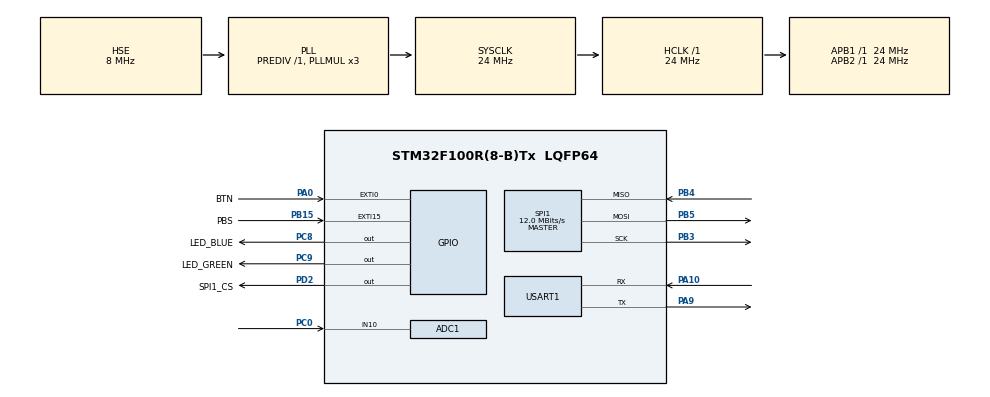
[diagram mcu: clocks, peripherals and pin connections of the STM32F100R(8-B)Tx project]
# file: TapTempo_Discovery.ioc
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Mcu.Family=STM32F1
TIM17.Prescaler=23999
VP_TIM17_VS_ClockSourceINT.Mode=Enable_Timer
ADC1.Rank-0\#ChannelRegularConversion=1
PD1-OSC_OUT.Mode=HSE-External-Oscillator
PA10.Mode=Asynchronous
SPI1.VirtualType=VM_MASTER
PC9.GPIO_Label=LED_GREEN
ADC1.ContinuousConvMode=ENABLE
TIM3.AutoReloadPreload=TIM_AUTORELOAD_PRELOAD_DISABLE
PC8.Signal=GPIO_Output
PD0-OSC_IN.Signal=RCC_OSC_IN
PC0.Signal=ADCx_IN10
PB15.Signal=GPXTI15
RCC.SYSCLKSource=RCC_SYSCLKSOURCE_PLLCLK
ProjectManager.StackSize=0x400
PA0-WKUP.GPIO_Label=BTN
PA0-WKUP.Signal=GPXTI0
RCC.PLLSource=RCC_PLLSOURCE_HSE
PD1-OSC_OUT.Signal=RCC_OSC_OUT
PC8.GPIO_Label=LED_BLUE
PA13.Signal=SYS_JTMS-SWDIO
PA9.Mode=Asynchronous
ProjectManager.TargetToolchain=STM32CubeIDE
SPI1.Direction=SPI_DIRECTION_2LINES
RCC.HCLKFreq_Value=24000000
RCC.APB2TimFreq_Value=24000000
TIM3.Period=25
PA9.Signal=USART1_TX
SPI1.CalculateBaudRate=12.0 MBits/s
RCC.AHBFreq_Value=24000000
PD0-OSC_IN.Mode=HSE-External-Oscillator
NVIC.EXTI15_10_IRQn=true\:1\:0\:true\:false\:true\:true\:true
ADC1.Channel-0\#ChannelRegularConversion=ADC_CHANNEL_10
PB15.GPIO_ModeDefaultEXTI=GPIO_MODE_IT_FALLING
PB3.Mode=Full_Duplex_Master
board=custom
RCC.PLLMUL=RCC_PLL_MUL3
NVIC.TIM3_IRQn=true\:0\:0\:false\:false\:true\:true\:true
TIM17.Period=1000
NVIC.TIM1_TRG_COM_TIM17_IRQn=true\:0\:0\:false\:false\:true\:true\:true
RCC.APB2Freq_Value=24000000
PB4.Mode=Full_Duplex_Master
PB15.GPIO_Label=PBS
VP_TIM2_VS_ClockSourceINT.Mode=Internal
SPI1.Mode=SPI_MODE_MASTER
PA14.Mode=Serial_Wire
TIM3.Prescaler=23999
PB5.Mode=Full_Duplex_Master
NVIC.TIM2_IRQn=true\:1\:0\:true\:false\:true\:true\:true
TIM2.Period=1000
PA13.Mode=Serial_Wire
Mcu.Name=STM32F100R(8-B)Tx
ADC1.SamplingTime-0\#ChannelRegularConversion=ADC_SAMPLETIME_1CYCLE_5
PB3.Signal=SPI1_SCK
NVIC.EXTI0_IRQn=true\:1\:0\:true\:false\:true\:true\:true
RCC.SYSCLKFreq_VALUE=24000000
Mcu.Package=LQFP64
PB5.Signal=SPI1_MOSI
TIM2.Prescaler=23999
ADC1.master=1
PB15.GPIO_PuPd=GPIO_PULLUP
USART1.VirtualMode=VM_ASYNC
PA10.Signal=USART1_RX
PA14.Signal=SYS_JTCK-SWCLK
SH.ADCx_IN10.0=ADC1_IN10,IN10
ProjectManager.HeapSize=0x200
NVIC.PriorityGroup=NVIC_PRIORITYGROUP_4
ADC1.NbrOfConversionFlag=1
RCC.APB1TimFreq_Value=24000000
TIM2.AutoReloadPreload=TIM_AUTORELOAD_PRELOAD_DISABLE
PC9.Signal=GPIO_Output
PD2.Signal=GPIO_Output
NVIC.USART1_IRQn=true\:0\:0\:false\:false\:true\:true\:true
RCC.APB1Freq_Value=24000000
SPI1.BaudRatePrescaler=SPI_BAUDRATEPRESCALER_2
VP_TIM3_VS_ClockSourceINT.Mode=Internal
PD2.GPIO_Label=SPI1_CS
PB4.Signal=SPI1_MISO

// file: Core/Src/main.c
/* USER CODE BEGIN Header */
/**
  ******************************************************************************
  * @file           : main.c
  * @brief          : Main program body
  ******************************************************************************
  * @attention
  *
  * <h2><center>&copy; Copyright (c) 2021 STMicroelectronics.
  * All rights reserved.</center></h2>
  *
  * This software component is licensed by ST under BSD 3-Clause license,
  * the "License"; You may not use this file except in compliance with the
  * License. You may obtain a copy of the License at:
  *                        opensource.org/licenses/BSD-3-Clause
  *
  ******************************************************************************
  */
/* USER CODE END Header */
#include "main.h"
#include "adc.h"
#include "spi.h"
#include "tim.h"
#include "usart.h"
#include "gpio.h"

void SystemClock_Config(void);

/* USER CODE BEGIN 0 */
void writePot(uint8_t val)
{
    uint8_t cmd = 0x11;

    // CS goes low
    HAL_GPIO_WritePin(SPI1_CS_GPIO_Port, SPI1_CS_Pin, GPIO_PIN_RESET);

    // Set val
    HAL_SPI_Transmit(&hspi1, &cmd, sizeof(cmd), 5000);
    HAL_SPI_Transmit(&hspi1, &val, sizeof(val), 5000);

    // CS goes high
    HAL_GPIO_WritePin(SPI1_CS_GPIO_Port, SPI1_CS_Pin, GPIO_PIN_SET);

}
/* USER CODE END 0 */

int main(void)
{

  /* MCU Configuration--------------------------------------------------------*/

  /* Reset of all peripherals, Initializes the Flash interface and the Systick. */
  HAL_Init();

  /* Configure the system clock */
  SystemClock_Config();

  /* Initialize all configured peripherals */
  MX_GPIO_Init();
  MX_SPI1_Init();
  MX_TIM2_Init();
  MX_TIM3_Init();
  MX_USART1_UART_Init();
  MX_ADC1_Init();
  MX_TIM17_Init();
  /* USER CODE BEGIN 2 */
  //HAL_TIM_Base_Start_IT(&htim1);
  HAL_TIM_Base_Start_IT(&htim2);
  /* USER CODE END 2 */

  /* Infinite loop */
  while (1)
  {

  }
}

void SystemClock_Config(void)
{
  RCC_OscInitTypeDef RCC_OscInitStruct = {0};
  RCC_ClkInitTypeDef RCC_ClkInitStruct = {0};
  RCC_PeriphCLKInitTypeDef PeriphClkInit = {0};

  /** Initializes the RCC Oscillators according to the specified parameters
  * in the RCC_OscInitTypeDef structure.
  */
  RCC_OscInitStruct.OscillatorType = RCC_OSCILLATORTYPE_HSE;
  RCC_OscInitStruct.HSEState = RCC_HSE_ON;
  RCC_OscInitStruct.HSEPredivValue = RCC_HSE_PREDIV_DIV1;
  RCC_OscInitStruct.PLL.PLLState = RCC_PLL_ON;
  RCC_OscInitStruct.PLL.PLLSource = RCC_PLLSOURCE_HSE;
  RCC_OscInitStruct.PLL.PLLMUL = RCC_PLL_MUL3;
  if (HAL_RCC_OscConfig(&RCC_OscInitStruct) != HAL_OK)
  {
    Error_Handler();
  }
  /** Initializes the CPU, AHB and APB buses clocks
  */
  RCC_ClkInitStruct.ClockType = RCC_CLOCKTYPE_HCLK|RCC_CLOCKTYPE_SYSCLK
                              |RCC_CLOCKTYPE_PCLK1|RCC_CLOCKTYPE_PCLK2;
  RCC_ClkInitStruct.SYSCLKSource = RCC_SYSCLKSOURCE_PLLCLK;
  RCC_ClkInitStruct.AHBCLKDivider = RCC_SYSCLK_DIV1;
  RCC_ClkInitStruct.APB1CLKDivider = RCC_HCLK_DIV1;
  RCC_ClkInitStruct.APB2CLKDivider = RCC_HCLK_DIV1;

  if (HAL_RCC_ClockConfig(&RCC_ClkInitStruct, FLASH_LATENCY_0) != HAL_OK)
  {
    Error_Handler();
  }
  PeriphClkInit.PeriphClockSelection = RCC_PERIPHCLK_ADC;
  PeriphClkInit.AdcClockSelection = RCC_ADCPCLK2_DIV2;
  if (HAL_RCCEx_PeriphCLKConfig(&PeriphClkInit) != HAL_OK)
  {
    Error_Handler();
  }
}

void Error_Handler(void)
{
  __disable_irq();
  while (1)
  {
  }
}

/************************ (C) COPYRIGHT STMicroelectronics *****END OF FILE****/
